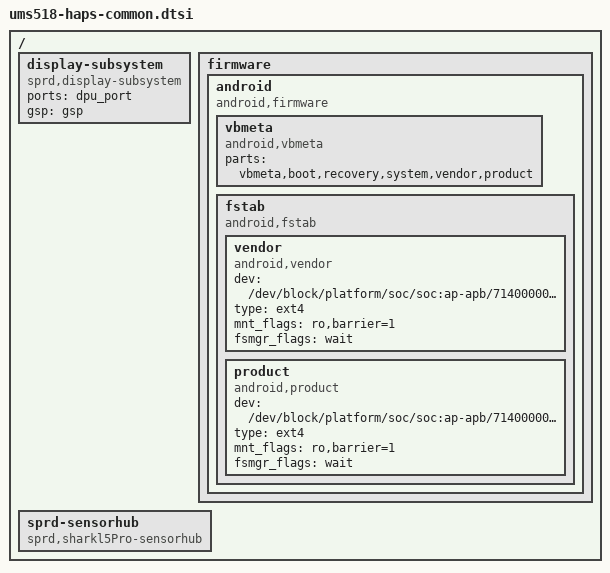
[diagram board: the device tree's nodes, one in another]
/*
 * Spreadtrum Sharkl5Pro board common DTS file
 *
 * Copyright (C) 2018, Spreadtrum Communications Inc.
 *
 * This file is licensed under a dual GPLv2 or X11 license.
 */

#include "lcd/lcd_dummy_mipi.dtsi"

/ {
	display-subsystem {
		compatible = "sprd,display-subsystem";
		ports = <&dpu_port>;
		gsp = <&gsp>;
	};

	firmware {
		android {
			compatible = "android,firmware";

			vbmeta {
				compatible = "android,vbmeta";
				parts = "vbmeta,boot,recovery,system,vendor,product";
			};

			fstab {
				compatible = "android,fstab";
				vendor {
					compatible = "android,vendor";
					dev = "/dev/block/platform/soc/soc:ap-apb/71400000.sdio/by-name/vendor";
					type = "ext4";
					mnt_flags = "ro,barrier=1";
					fsmgr_flags = "wait";
				};
				product {
					compatible = "android,product";
					dev = "/dev/block/platform/soc/soc:ap-apb/71400000.sdio/by-name/product";
					type = "ext4";
					mnt_flags = "ro,barrier=1";
					fsmgr_flags = "wait";
				};
			};
		};
	};

	sprd-sensorhub {
		 compatible = "sprd,sharkl5Pro-sensorhub";
	};
};
